# PIC16LF1454 register map
Vendor: Microchip
Architecture 16Exxx. Special function registers and configuration words.
Registers are 8-bit, read-write, no defined reset value unless marked. A register's access mark holds for its fields unless they carry their own. Addresses are absolute, and some are shared; only a register's first bit layout is shown; lines under a group give offsets from that group; [hi:lo] are bit positions; {n}, {i} and the like mark numbered series; 'fields as' and 'values as' point back to an identical list; <NAME> marks a mode.

## Further device data
pins=1: VDD; 2: RA5/SOSCI/T1CKI/PWM2/CLKIN/OSC1; 3: RA4/SOSCO/T1G/SDO/CLKOUT/OSC2/CLKR; 4: RA3/T1G/SS/MCLR/VPP; 5: RC5/RX_DT/T0CKI/PWM1; 6: RC4/TX_CK; 7: RC3/SS/PWM2/CLKR; 8: RC2/SDO; 9: RC1/INT/SDI/SDA/ICSPCLK; 10: RC0/SCK/SCL/ICSPDAT; 11: VUSB3V3; 12: RA1/D-/ICSPCLK; 13: RA0/D+/ICSPDAT; 14: VSS

## usb_fscore
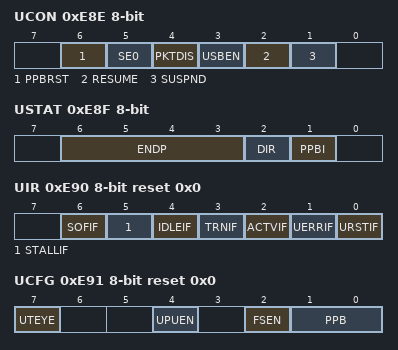
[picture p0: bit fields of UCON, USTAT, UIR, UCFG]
0xE8E UCON — (power-on value -0x0000-)
  [6] PPBRST, [5] SE0 ro, [4] PKTDIS, [3] USBEN, [2] RESUME, [1] SUSPND
0xE8F USTAT ro — (power-on value -xxxxxx-)
  [6:3] ENDP, [2] DIR, [1] PPBI
0xE90 UIR reset 0x0
  [6] SOFIF, [5] STALLIF, [4] IDLEIF, [3] TRNIF, [2] ACTVIF, [1] UERRIF ro, [0] URSTIF
0xE91 UCFG reset 0x0
  [7] UTEYE, [4] UPUEN, [2] FSEN, [1:0] PPB
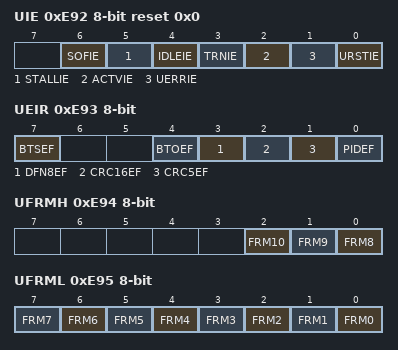
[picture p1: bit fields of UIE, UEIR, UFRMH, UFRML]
0xE92 UIE reset 0x0
  [6] SOFIE, [5] STALLIE, [4] IDLEIE, [3] TRNIE, [2] ACTVIE, [1] UERRIE, [0] URSTIE
0xE93 UEIR ro — (power-on value x--xxxxx)
  [7] BTSEF, [4] BTOEF, [3] DFN8EF, [2] CRC16EF, [1] CRC5EF, [0] PIDEF
0xE94 UFRMH — (power-on value -----xxx)
  [2] FRM10, [1] FRM9, [0] FRM8
0xE95 UFRML — (power-on value xxxxxxxx)
  [n] FRM{n} (n=0..7)
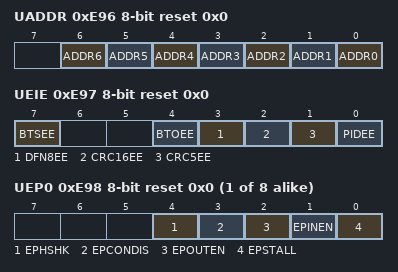
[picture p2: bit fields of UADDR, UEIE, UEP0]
0xE96 UADDR reset 0x0
  [n] ADDR{n} (n=0..6)
0xE97 UEIE reset 0x0
  [7] BTSEE, [4] BTOEE, [3] DFN8EE, [2] CRC16EE, [1] CRC5EE, [0] PIDEE
{0xE98+i} UEP{i} reset 0x0 (i=0..7)
  [4] EPHSHK, [3] EPCONDIS, [2] EPOUTEN, [1] EPINEN, [0] EPSTALL

## CONFIG — Configuration words, addresses in ProgramSpace
0x8007 CONFIG1 14-bit reset 0x3FFF
  [13] FCMEN — Fail-Safe Clock Monitor Enable
    1=ON (Fail-Safe Clock Monitor is enabled); 0=OFF (Fail-Safe Clock Monitor is disabled)
  [12] IESO — Internal/External Switchover Mode
    1=ON (Internal/External Switchover Mode is enabled); 0=OFF (Internal/External Switchover Mode is disabled)
  [11] CLKOUTEN — Clock Out Enable
    1=OFF (CLKOUT function is disabled. I/O or oscillator function on the CLKOUT pin); 0=ON (CLKOUT function is enabled on the CLKOUT pin)
  [10:9] BOREN — Brown-out Reset Enable
    3=ON (Brown-out Reset enabled); 2=NSLEEP (Brown-out Reset enabled while running and disabled in Sleep); 1=SBODEN (Brown-out Reset controlled by the SBOREN bit in the BORCON register); 0=OFF (Brown-out Reset disabled)
  [7] CP — Flash Program Memory Code Protection
    1=OFF (Program memory code protection is disabled); 0=ON (Program memory code protection is enabled)
  [6] MCLRE — MCLR Pin Function Select
    1=ON (MCLR/VPP pin function is MCLR); 0=OFF (MCLR/VPP pin function is digital input)
  [5] PWRTE — Power-up Timer Enable
    1=OFF (PWRT disabled); 0=ON (PWRT enabled)
  [4:3] WDTE — Watchdog Timer Enable
    3=ON (WDT enabled); 2=NSLEEP (WDT enabled while running and disabled in Sleep); 1=SWDTEN (WDT controlled by the SWDTEN bit in the WDTCON register); 0=OFF (WDT disabled)
  [2:0] FOSC — Oscillator Selection Bits
    7=ECH (ECH, External Clock, High Power Mode (4-20 MHz): device clock supplied to CLKIN pins); 6=ECM (ECM, External Clock, Medium Power Mode (0.5-4 MHz): device clock supplied to CLKIN pins); 5=ECL (ECL, External Clock, Low Power Mode (0-0.5 MHz): device clock supplied to CLKIN pins); 4=INTOSC (INTOSC oscillator: I/O function on CLKIN pin); 3=EXTRC (EXTRC oscillator: External RC circuit connected to CLKIN pin); 2=HS (HS Oscillator, High-speed crystal/resonator connected between OSC1 and OSC2 pins); 1=XT (XT Oscillator, Crystal/resonator connected between OSC1 and OSC2 pins); 0=LP (LP Oscillator, Low-power crystal connected between OSC1 and OSC2 pins)
0x8008 CONFIG2 14-bit reset 0x3FFF
  [13] LVP — Low-Voltage Programming Enable
    1=ON (Low-voltage programming enabled); 0=OFF (High-voltage on MCLR/VPP must be used for programming)
  [11] LPBOR — Low-Power Brown Out Reset
    1=OFF (Low-Power BOR is disabled); 0=ON (Low-Power BOR is enabled)
  [10] BORV — Brown-out Reset Voltage Selection
    1=LO (Brown-out Reset Voltage (Vbor), low trip point selected.); 0=HI (Brown-out Reset Voltage (Vbor), high trip point selected.)
  [9] STVREN — Stack Overflow/Underflow Reset Enable
    1=ON (Stack Overflow or Underflow will cause a Reset); 0=OFF (Stack Overflow or Underflow will not cause a Reset)
  [8] PLLEN — PLL Enable Bit
    1=ENABLED (3x or 4x PLL Enabled); 0=DISABLED (3x or 4x PLL Disabled)
  [7] PLLMULT — PLL Multiplier Selection Bit
    1=3x (3x Output Frequency Selected); 0=4x (4x Output Frequency Selected)
  [6] USBLSCLK — USB Low Speed Clock Selection bit
    1=48MHz (System clock expects 48 MHz, FS/LS USB CLKENs divide-by is set to 8.); 0=24MHz (System clock expects 24 MHz, FS/LS USB CLKENs divide-by is set to 4.)
  [5:4] CPUDIV — CPU System Clock Selection Bit
    3=CLKDIV6 (CPU system clock divided by 6); 2=CLKDIV3 (CPU system clock divided by 3); 1=CLKDIV2 (CPU system clock divided by 2); 0=NOCLKDIV (NO CPU system divide)
  [1:0] WRT — Flash Memory Self-Write Protection
    3=OFF (Write protection off); 2=BOOT (000h to 1FFh write protected, 200h to 1FFFh may be modified by PMCON control); 1=HALF (000h to 0FFFh write protected, 1000h to 1FFFh may be modified by PMCON control); 0=ALL (000h to 1FFFh write protected, no addresses may be modified by PMCON control)
